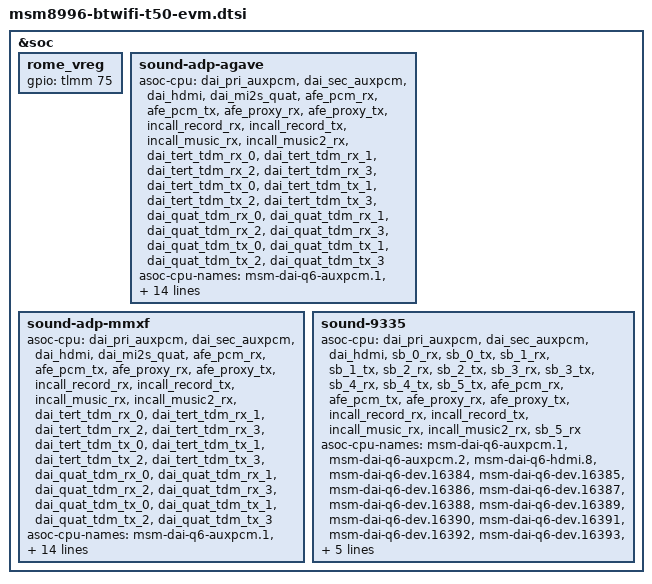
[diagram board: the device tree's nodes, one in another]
/* Copyright (c) 2016, The Linux Foundation. All rights reserved.
 *
 * This program is free software; you can redistribute it and/or modify
 * it under the terms of the GNU General Public License version 2 and
 * only version 2 as published by the Free Software Foundation.
 *
 * This program is distributed in the hope that it will be useful,
 * but WITHOUT ANY WARRANTY; without even the implied warranty of
 * MERCHANTABILITY or FITNESS FOR A PARTICULAR PURPOSE.  See the
 * GNU General Public License for more details.
 */

/*
 * msm8996-btwifi-t50-evm: change rome_vreg to msm_gpio75 of EVM board
 */
&soc
{
	/* Rome 3.3V supply */
	rome_vreg: rome_vreg {
		gpio = <&tlmm 75 0>;
	};

	sound-adp-agave {
		asoc-cpu = <&dai_pri_auxpcm>, <&dai_sec_auxpcm>, <&dai_hdmi>,
				/*<&dai_mi2s>,*/ <&dai_mi2s_quat>,
				<&afe_pcm_rx>, <&afe_pcm_tx>,
				<&afe_proxy_rx>, <&afe_proxy_tx>,
				<&incall_record_rx>, <&incall_record_tx>,
				<&incall_music_rx>, <&incall_music2_rx>,
				<&dai_tert_tdm_rx_0>, <&dai_tert_tdm_rx_1>,
				<&dai_tert_tdm_rx_2>, <&dai_tert_tdm_rx_3>,
				<&dai_tert_tdm_tx_0>, <&dai_tert_tdm_tx_1>,
				<&dai_tert_tdm_tx_2>, <&dai_tert_tdm_tx_3>,
				<&dai_quat_tdm_rx_0>, <&dai_quat_tdm_rx_1>,
				<&dai_quat_tdm_rx_2>, <&dai_quat_tdm_rx_3>,
				<&dai_quat_tdm_tx_0>, <&dai_quat_tdm_tx_1>,
				<&dai_quat_tdm_tx_2>, <&dai_quat_tdm_tx_3>;
		asoc-cpu-names = "msm-dai-q6-auxpcm.1", "msm-dai-q6-auxpcm.2",
				"msm-dai-q6-hdmi.8",
				/*"msm-dai-q6-mi2s.2",*/ "msm-dai-q6-mi2s.3",
				"msm-dai-q6-dev.224", "msm-dai-q6-dev.225",
				"msm-dai-q6-dev.241", "msm-dai-q6-dev.240",
				"msm-dai-q6-dev.32771", "msm-dai-q6-dev.32772",
				"msm-dai-q6-dev.32773", "msm-dai-q6-dev.32770",
				"msm-dai-q6-tdm.36896", "msm-dai-q6-tdm.36898",
				"msm-dai-q6-tdm.36900", "msm-dai-q6-tdm.36902",
				"msm-dai-q6-tdm.36897", "msm-dai-q6-tdm.36899",
				"msm-dai-q6-tdm.36901", "msm-dai-q6-tdm.36903",
				"msm-dai-q6-tdm.36912", "msm-dai-q6-tdm.36914",
				"msm-dai-q6-tdm.36916", "msm-dai-q6-tdm.36918",
				"msm-dai-q6-tdm.36913", "msm-dai-q6-tdm.36915",
				"msm-dai-q6-tdm.36917", "msm-dai-q6-tdm.36919";
	};

	sound-adp-mmxf {
		asoc-cpu = <&dai_pri_auxpcm>, <&dai_sec_auxpcm>, <&dai_hdmi>,
				/*<&dai_mi2s>,*/ <&dai_mi2s_quat>,
				<&afe_pcm_rx>, <&afe_pcm_tx>,
				<&afe_proxy_rx>, <&afe_proxy_tx>,
				<&incall_record_rx>, <&incall_record_tx>,
				<&incall_music_rx>, <&incall_music2_rx>,
				<&dai_tert_tdm_rx_0>, <&dai_tert_tdm_rx_1>,
				<&dai_tert_tdm_rx_2>, <&dai_tert_tdm_rx_3>,
				<&dai_tert_tdm_tx_0>, <&dai_tert_tdm_tx_1>,
				<&dai_tert_tdm_tx_2>, <&dai_tert_tdm_tx_3>,
				<&dai_quat_tdm_rx_0>, <&dai_quat_tdm_rx_1>,
				<&dai_quat_tdm_rx_2>, <&dai_quat_tdm_rx_3>,
				<&dai_quat_tdm_tx_0>, <&dai_quat_tdm_tx_1>,
				<&dai_quat_tdm_tx_2>, <&dai_quat_tdm_tx_3>;
		asoc-cpu-names = "msm-dai-q6-auxpcm.1", "msm-dai-q6-auxpcm.2",
				"msm-dai-q6-hdmi.8",
				/*"msm-dai-q6-mi2s.2",*/ "msm-dai-q6-mi2s.3",
				"msm-dai-q6-dev.224", "msm-dai-q6-dev.225",
				"msm-dai-q6-dev.241", "msm-dai-q6-dev.240",
				"msm-dai-q6-dev.32771", "msm-dai-q6-dev.32772",
				"msm-dai-q6-dev.32773", "msm-dai-q6-dev.32770",
				"msm-dai-q6-tdm.36896", "msm-dai-q6-tdm.36898",
				"msm-dai-q6-tdm.36900", "msm-dai-q6-tdm.36902",
				"msm-dai-q6-tdm.36897", "msm-dai-q6-tdm.36899",
				"msm-dai-q6-tdm.36901", "msm-dai-q6-tdm.36903",
				"msm-dai-q6-tdm.36912", "msm-dai-q6-tdm.36914",
				"msm-dai-q6-tdm.36916", "msm-dai-q6-tdm.36918",
				"msm-dai-q6-tdm.36913", "msm-dai-q6-tdm.36915",
				"msm-dai-q6-tdm.36917", "msm-dai-q6-tdm.36919";
	};

	sound-9335 {
		asoc-cpu = <&dai_pri_auxpcm>, <&dai_sec_auxpcm>, <&dai_hdmi>, /*<&dai_mi2s>,*/
				<&sb_0_rx>, <&sb_0_tx>, <&sb_1_rx>, <&sb_1_tx>,
				<&sb_2_rx>, <&sb_2_tx>, <&sb_3_rx>, <&sb_3_tx>,
				<&sb_4_rx>, <&sb_4_tx>, <&sb_5_tx>, <&afe_pcm_rx>,
				<&afe_pcm_tx>, <&afe_proxy_rx>, <&afe_proxy_tx>,
				<&incall_record_rx>, <&incall_record_tx>,
				<&incall_music_rx>, <&incall_music2_rx>,
				<&sb_5_rx>;
		asoc-cpu-names = "msm-dai-q6-auxpcm.1", "msm-dai-q6-auxpcm.2",
				"msm-dai-q6-hdmi.8", /*"msm-dai-q6-mi2s.2",*/
				"msm-dai-q6-dev.16384", "msm-dai-q6-dev.16385",
				"msm-dai-q6-dev.16386", "msm-dai-q6-dev.16387",
				"msm-dai-q6-dev.16388", "msm-dai-q6-dev.16389",
				"msm-dai-q6-dev.16390", "msm-dai-q6-dev.16391",
				"msm-dai-q6-dev.16392", "msm-dai-q6-dev.16393",
				"msm-dai-q6-dev.16395", "msm-dai-q6-dev.224",
				"msm-dai-q6-dev.225", "msm-dai-q6-dev.241",
				"msm-dai-q6-dev.240", "msm-dai-q6-dev.32771",
				"msm-dai-q6-dev.32772", "msm-dai-q6-dev.32773",
				"msm-dai-q6-dev.32770", "msm-dai-q6-dev.16394";
	};
};

/delete-node/ &tert_mi2s_sleep;
/delete-node/ &tert_mi2s_active;
/delete-node/ &tert_mi2s_sd0_sleep;
/delete-node/ &tert_mi2s_sd0_active;
/delete-node/ &tert_tdm_sleep;
/delete-node/ &tert_tdm_active;
/delete-node/ &tert_tdm_din_sleep;
/delete-node/ &tert_tdm_din_active;
/delete-node/ &dai_mi2s;

